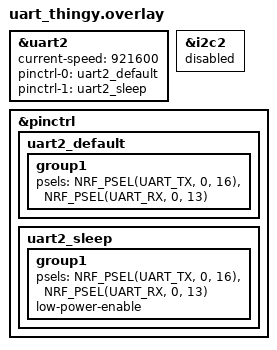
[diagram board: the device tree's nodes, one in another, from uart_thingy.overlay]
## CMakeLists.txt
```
#
# Copyright (c) 2019 Nordic Semiconductor
#
# SPDX-License-Identifier: LicenseRef-Nordic-5-Clause
#

cmake_minimum_required(VERSION 3.20.0)

find_package(Zephyr REQUIRED HINTS $ENV{ZEPHYR_BASE})
project(gnss)

zephyr_library_sources(src/main.c)
zephyr_library_sources(src/uart_api.c)

zephyr_library_sources_ifdef(CONFIG_GNSS_SAMPLE_ASSISTANCE_NRF_CLOUD src/assistance.c)
zephyr_library_sources_ifdef(CONFIG_GNSS_SAMPLE_ASSISTANCE_SUPL src/assistance_supl.c)
zephyr_library_sources_ifdef(CONFIG_GNSS_SAMPLE_ASSISTANCE_MINIMAL src/assistance_minimal.c)
zephyr_library_sources_ifdef(CONFIG_GNSS_SAMPLE_ASSISTANCE_MINIMAL src/mcc_location_table.c)
```

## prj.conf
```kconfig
#
# Copyright (c) 2019 Nordic Semiconductor ASA
#
# SPDX-License-Identifier: LicenseRef-Nordic-5-Clause
#

# General
CONFIG_FPU=y
CONFIG_NRF_MODEM_LIB=y
CONFIG_STDOUT_CONSOLE=y
CONFIG_UART_INTERRUPT_DRIVEN=y
CONFIG_PICOLIBC_IO_FLOAT=y
CONFIG_LOG=y
CONFIG_LOG_MODE_IMMEDIATE=y

# GNSS sample
# Enable to use nRF Cloud A-GNSS
CONFIG_GNSS_SAMPLE_ASSISTANCE_NRF_CLOUD=n

# LTE Link Control
CONFIG_LTE_LINK_CONTROL=y
# Request eDRX from the network
CONFIG_LTE_EDRX_REQ=y
# PSM requested periodic TAU 8 hours
CONFIG_LTE_PSM_REQ_RPTAU="00101000"
# PSM requested active time 6 seconds
CONFIG_LTE_PSM_REQ_RAT="00000011"

# AT Host library - Used to send AT commands directy from an UART terminal and to allow
#		    integration with nRF Connect for Desktop LTE Link monitor application.
CONFIG_AT_HOST_LIBRARY=y

# Networking
CONFIG_NETWORKING=y
CONFIG_NET_SOCKETS_OFFLOAD=y
CONFIG_NET_SOCKETS=y
CONFIG_POSIX_API=y
# Disable native network stack to save some memory
CONFIG_NET_NATIVE=n

# Memory and stack configuration
CONFIG_HEAP_MEM_POOL_SIZE=2048
CONFIG_MAIN_STACK_SIZE=4096
CONFIG_SYSTEM_WORKQUEUE_STACK_SIZE=1536

# UART
CONFIG_SERIAL=y
CONFIG_NRFX_UARTE2=y
CONFIG_UART_INTERRUPT_DRIVEN=y
CONFIG_UART_2_INTERRUPT_DRIVEN=y

#Setup
CONFIG_GNSS_SAMPLE_ASSISTANCE_NONE=y
CONFIG_GNSS_SAMPLE_MODE_TTFF_TEST=y

CONFIG_SENSOR=n
CONFIG_BME680=n
CONFIG_REGULATOR_ADP5360=n
CONFIG_I2C=n
CONFIG_ADP536X=n
```

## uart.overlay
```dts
&uart2 {
    status = "okay";
    current-speed = <921600>;
    pinctrl-0 = <&uart2_default>;
    pinctrl-1 = <&uart2_sleep>;
    pinctrl-names = "default", "sleep";
};

&uart2_default {
    group1 {
        psels = <NRF_PSEL(UART_RX, 0, 13)>,
                <NRF_PSEL(UART_TX, 0, 16)>;
    };
};

&uart2_sleep {
    group1 {
        psels = <NRF_PSEL(UART_RX, 0, 13)>,
            <NRF_PSEL(UART_TX, 0, 16)>;
        low-power-enable;
    };
};
```

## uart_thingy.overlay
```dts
&uart2 {
    status = "okay";
    current-speed = <921600>;
    pinctrl-0 = <&uart2_default>;
    pinctrl-1 = <&uart2_sleep>;
    pinctrl-names = "default", "sleep";
};

&i2c2 {
    status="disabled";
};


&pinctrl {
    uart2_default: uart2_default {
        group1 {
            psels = <NRF_PSEL(UART_TX, 0, 16)>, /* Pin P1.10 as TX */
                    <NRF_PSEL(UART_RX, 0, 13)>; /* Pin P1.11 as RX */
        };
    };

    uart2_sleep: uart2_sleep {
        group1 {
            psels = <NRF_PSEL(UART_TX, 0, 16)>, /* TX pin disabled */
                    <NRF_PSEL(UART_RX, 0, 13)>; /* RX pin disabled */
            low-power-enable;
        };
    };
};
```

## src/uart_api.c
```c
/* ============================================================================================== */
/*                                            INCLUDES                                            */
#include <zephyr/kernel.h>
#include <zephyr/logging/log.h>
#include <zephyr/drivers/uart.h>
#include <string.h>


/* ============================================================================================== */

/* ============================================================================================== */
/*                                        DEFINES/TYPEDEFS                                        */
#define UART_BUFFER_SIZE 256

/* ============================================================================================== */
/*                                   PRIVATE FUNCTION DEFINITIONS                                 */
static void uart_irq_handler(const struct device *dev, void *user_data);

/* ============================================================================================== */
/*                                        PRIVATE VARIABLES                                       */
const struct device *uart_dev;
static uint8_t uart_rx_buf[UART_BUFFER_SIZE];
static bool uart_enabled = false;
K_MSGQ_DEFINE(uart_rx_q, sizeof(uart_rx_buf), 5, 2);

LOG_MODULE_REGISTER(UART, LOG_LEVEL_DBG);
/* ============================================================================================== */
/*                                        PUBLIC FUNCTIONS                                        */


void uart_enable(void)
{
    if (!uart_enabled) {
        uart_rx_enable(uart_dev, uart_rx_buf, sizeof(uart_rx_buf), SYS_FOREVER_MS);
        uart_enabled = true;
        LOG_INF("UART enabled.");
    }
}

void uart_disable(void)
{
    if (uart_enabled) {
        uart_rx_disable(uart_dev);
        uart_enabled = false;
        LOG_INF("UART disabled for low power.");
    }
}

int uart_init(void)
{
    uart_dev = DEVICE_DT_GET(DT_NODELABEL(uart2));
    if (!device_is_ready(uart_dev)) {
        LOG_ERR("UART device not ready.");
        return -ENODEV;
    }

    uart_irq_callback_set(uart_dev, uart_irq_handler);
    uart_irq_rx_enable(uart_dev);

    uart_enable();
    LOG_INF("UART initialized successfully.");
    return 0;
}

void uart_print(uint8_t *buf, uint16_t len)
{
    for (int i = 0; i < len; i++)
    {
        uart_poll_out(uart_dev, buf[i]);
    }
}

int uart_wait_for_msg(uint8_t *buffer, uint16_t max_len, k_timeout_t timeout)
{
    if (!buffer)
        return -EINVAL;
    return k_msgq_get(&uart_rx_q, buffer, timeout);
}
/* ============================================================================================== */
/*                                         PRIVATE FUNCTIONS                                      */
static void uart_irq_handler(const struct device *dev, void *user_data)
{
    static size_t pos = 0;
    uint8_t byte;

    while (uart_irq_update(dev) && uart_irq_is_pending(dev))
    {
        if (uart_irq_rx_ready(dev))
        {
            uart_fifo_read(dev, &byte, 1);
            uart_rx_buf[pos++] = byte;

            if (byte == '\n' || pos >= UART_BUFFER_SIZE - 1) {
                uart_rx_buf[pos] = '\0';
                LOG_DBG("Got msg %s", uart_rx_buf);
                k_msgq_put(&uart_rx_q, uart_rx_buf, K_NO_WAIT);
                pos = 0;
            }
        }
    }
}
```

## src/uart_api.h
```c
#ifndef __UART_API_H__
#define __UART_API_H__

/* ============================================================================================== */
/*                                            INCLUDES                                            */
#include <zephyr/kernel.h>


/* ============================================================================================== */

/* ============================================================================================== */
/*                                        DEFINES/TYPEDEFS                                        */
extern struct k_msgq uart_rx_q;
/* ============================================================================================== */
/*                                        PUBLIC FUNCTIONS                                        */


void uart_enable(void);
void uart_disable(void);
int uart_init(void);
int uart_wait_for_msg(uint8_t *buffer, uint16_t max_len, k_timeout_t timeout);
void uart_print(uint8_t *buf, uint16_t len);
/* ============================================================================================== */
/*                                         PRIVATE FUNCTIONS                                      */
#endif
```
